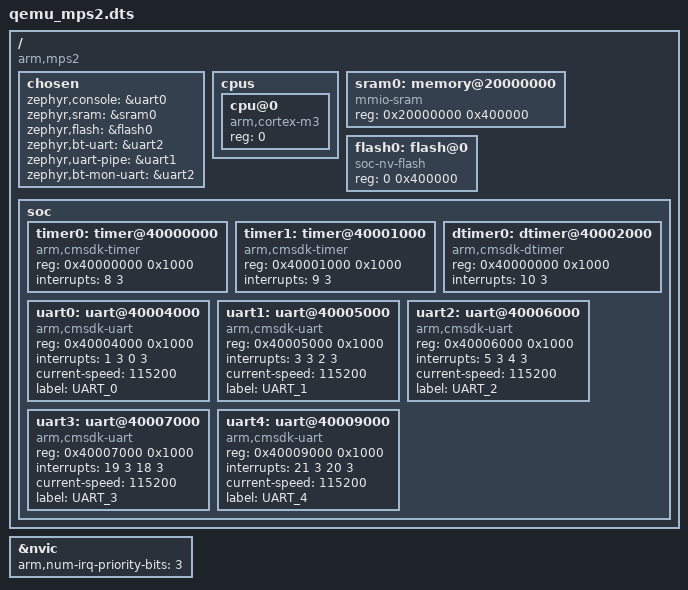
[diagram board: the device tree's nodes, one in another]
/dts-v1/;

#include <arm/armv7-m.dtsi>

/ {
	compatible = "arm,mps2";
	#address-cells = <1>;
	#size-cells = <1>;

	chosen {
		zephyr,console = &uart0;
		zephyr,sram = &sram0;
		zephyr,flash = &flash0;
		zephyr,bt-uart = &uart2;
		zephyr,uart-pipe = &uart1;
		zephyr,bt-mon-uart = &uart2;
	};

	cpus {
		#address-cells = <1>;
		#size-cells = <0>;

		cpu@0 {
			compatible = "arm,cortex-m3";
			reg = <0>;
		};
	};

	sram0: memory@20000000 {
		compatible = "mmio-sram";
		reg = <0x20000000 0x400000>;
	};

	flash0: flash@0 {
		compatible = "soc-nv-flash";
		reg = <0 0x400000>;
	};

	soc {
		timer0: timer@40000000 {
			compatible = "arm,cmsdk-timer";
			reg = <0x40000000 0x1000>;
			interrupts = <8 3>;
		};

		timer1: timer@40001000 {
			compatible = "arm,cmsdk-timer";
			reg = <0x40001000 0x1000>;
			interrupts = <9 3>;
		};

		dtimer0: dtimer@40002000 {
			compatible = "arm,cmsdk-dtimer";
			reg = <0x40000000 0x1000>;
			interrupts = <10 3>;
		};

		uart0: uart@40004000 {
			compatible = "arm,cmsdk-uart";
			reg = <0x40004000 0x1000>;
			interrupts = <1 3 0 3>;
			interrupt-names = "tx", "rx";
			current-speed = <115200>;
			label = "UART_0";
		};

		uart1: uart@40005000 {
			compatible = "arm,cmsdk-uart";
			reg = <0x40005000 0x1000>;
			interrupts = <3 3 2 3>;
			interrupt-names = "tx", "rx";
			current-speed = <115200>;
			label = "UART_1";
		};

		uart2: uart@40006000 {
			compatible = "arm,cmsdk-uart";
			reg = <0x40006000 0x1000>;
			interrupts = <5 3 4 3>;
			interrupt-names = "tx", "rx";
			current-speed = <115200>;
			label = "UART_2";
		};

		uart3: uart@40007000 {
			compatible = "arm,cmsdk-uart";
			reg = <0x40007000 0x1000>;
			interrupts = <19 3 18 3>;
			interrupt-names = "tx", "rx";
			current-speed = <115200>;
			label = "UART_3";
		};

		uart4: uart@40009000 {
			compatible = "arm,cmsdk-uart";
			reg = <0x40009000 0x1000>;
			interrupts = <21 3 20 3>;
			interrupt-names = "tx", "rx";
			current-speed = <115200>;
			label = "UART_4";
		};
	};
};

&nvic {
	arm,num-irq-priority-bits = <3>;
};
